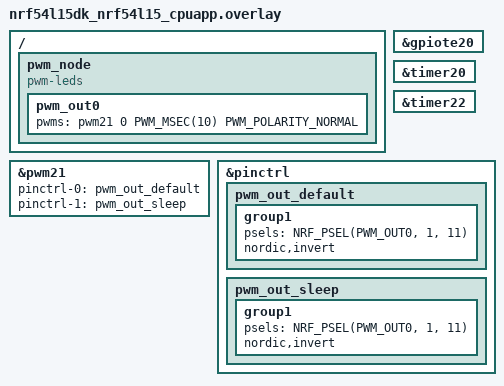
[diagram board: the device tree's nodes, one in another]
&gpiote20 {
    status = "okay";
};

&timer20 {
    status = "okay";
};

&timer22 {
    status = "okay";
};

&pwm21 {
    status = "okay";
    pinctrl-0 = <&pwm_out_default>;
    pinctrl-1 = <&pwm_out_sleep>;
    pinctrl-names = "default", "sleep";
};

&pinctrl {
    pwm_out_default: pwm_out_default {
        group1 {
            psels = <NRF_PSEL(PWM_OUT0, 1, 11)>;
            nordic,invert;
        };
    };

    pwm_out_sleep: pwm_out_sleep {
        group1 {
            psels = <NRF_PSEL(PWM_OUT0, 1, 11)>;
            nordic,invert;
        };
    };
};

//STEP 2.3 Disable internal pull-up on button 0

/ { pwm_node: pwm_node{
        compatible = "pwm-leds";
        pwm_out0: pwm_out0 {
            pwms = <&pwm21 0 PWM_MSEC(10) PWM_POLARITY_NORMAL>;
        };
    };
};
